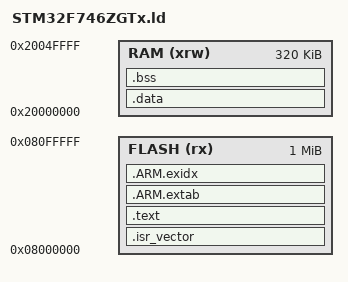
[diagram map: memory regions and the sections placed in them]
/* Entry Point */
ENTRY(Reset_Handler)

/* Specify the memory areas */
MEMORY
{
  FLASH (rx)      : ORIGIN = 0x08000000, LENGTH = 1024K
  RAM (xrw)       : ORIGIN = 0x20000000, LENGTH = 320K
}

/* Define output sections */
SECTIONS
{
  .isr_vector :
  {
    KEEP(*(.isr_vector))
  } > FLASH

  .text :
  {
    *(.text*)
    *(.rodata*)
    KEEP(*(.init))
    KEEP(*(.fini))
  } > FLASH

  .ARM.extab : { *(.ARM.extab* .gnu.linkonce.armextab.*) } > FLASH
  .ARM.exidx : { *(.ARM.exidx* .gnu.linkonce.armexidx.*) } > FLASH

  .data : AT (ADDR(.text) + SIZEOF(.text))
  {
    _sidata = LOADADDR(.data);
    _sdata = .;
    *(.data*)
    _edata = .;
  } > RAM

  .bss :
  {
    _sbss = .;
    *(.bss*)
    *(COMMON)
    _ebss = .;
  } > RAM

  . = ALIGN(4);
  _end = .;
  PROVIDE(end = .);
}
